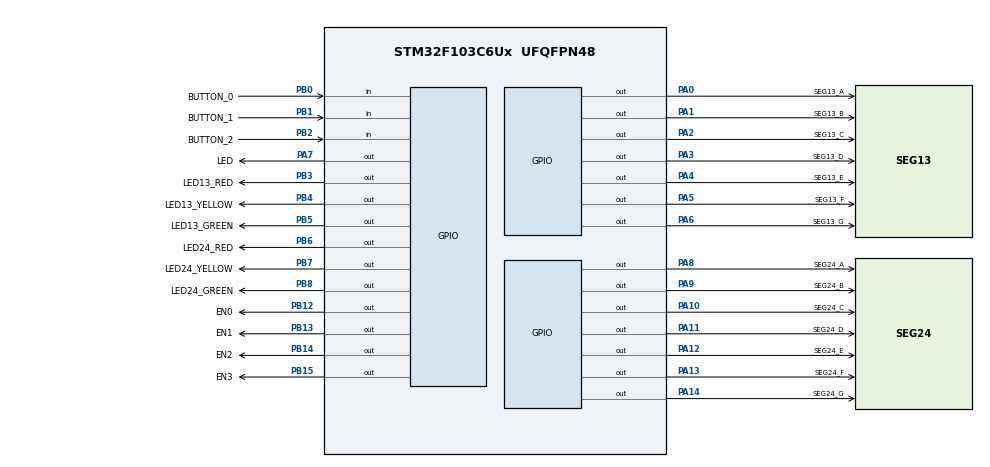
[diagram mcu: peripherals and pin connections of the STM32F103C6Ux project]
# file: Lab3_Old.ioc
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Mcu.Family=STM32F1
Mcu.Name=STM32F103C6Ux
Mcu.Package=UFQFPN48
NVIC.PriorityGroup=NVIC_PRIORITYGROUP_4
NVIC.TIM2_IRQn=true\:0\:0\:false\:false\:true\:true\:true\:true
PA0-WKUP.GPIO_Label=SEG13_A
PA0-WKUP.Signal=GPIO_Output
PA1.GPIO_Label=SEG13_B
PA1.Signal=GPIO_Output
PA10.GPIO_Label=SEG24_C
PA10.Signal=GPIO_Output
PA11.GPIO_Label=SEG24_D
PA11.Signal=GPIO_Output
PA12.GPIO_Label=SEG24_E
PA12.Signal=GPIO_Output
PA13.GPIO_Label=SEG24_F
PA13.Signal=GPIO_Output
PA14.GPIO_Label=SEG24_G
PA14.Signal=GPIO_Output
PA2.GPIO_Label=SEG13_C
PA2.Signal=GPIO_Output
PA3.GPIO_Label=SEG13_D
PA3.Signal=GPIO_Output
PA4.GPIO_Label=SEG13_E
PA4.Signal=GPIO_Output
PA5.GPIO_Label=SEG13_F
PA5.Signal=GPIO_Output
PA6.GPIO_Label=SEG13_G
PA6.Signal=GPIO_Output
PA7.GPIO_Label=LED
PA7.Signal=GPIO_Output
PA8.GPIO_Label=SEG24_A
PA8.Signal=GPIO_Output
PA9.GPIO_Label=SEG24_B
PA9.Signal=GPIO_Output
PB0.GPIO_Label=BUTTON_0
PB0.Signal=GPIO_Input
PB1.GPIO_Label=BUTTON_1
PB1.Signal=GPIO_Input
PB12.GPIO_Label=EN0
PB12.Signal=GPIO_Output
PB13.GPIO_Label=EN1
PB13.Signal=GPIO_Output
PB14.GPIO_Label=EN2
PB14.Signal=GPIO_Output
PB15.GPIO_Label=EN3
PB15.Signal=GPIO_Output
PB2.GPIO_Label=BUTTON_2
PB2.Signal=GPIO_Input
PB3.GPIO_Label=LED13_RED
PB3.Signal=GPIO_Output
PB4.GPIO_Label=LED13_YELLOW
PB4.Signal=GPIO_Output
PB5.GPIO_Label=LED13_GREEN
PB5.Signal=GPIO_Output
PB6.GPIO_Label=LED24_RED
PB6.Signal=GPIO_Output
PB7.GPIO_Label=LED24_YELLOW
PB7.Signal=GPIO_Output
PB8.GPIO_Label=LED24_GREEN
PB8.Signal=GPIO_Output
ProjectManager.HeapSize=0x200
ProjectManager.StackSize=0x400
ProjectManager.TargetToolchain=STM32CubeIDE
RCC.APB1Freq_Value=8000000
RCC.APB2Freq_Value=8000000
TIM2.Period=9
TIM2.Prescaler=7999
VP_SYS_VS_ND.Mode=No_Debug
VP_TIM2_VS_ClockSourceINT.Mode=Internal
board=custom

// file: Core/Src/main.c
/* USER CODE BEGIN Header */
/**
  ******************************************************************************
  * @file           : main.c
  * @brief          : Main program body
  ******************************************************************************
  * @attention
  *
  * Copyright (c) 2024 STMicroelectronics.
  * All rights reserved.
  *
  * This software is licensed under terms that can be found in the LICENSE file
  * in the root directory of this software component.
  * If no LICENSE file comes with this software, it is provided AS-IS.
  *
  ******************************************************************************
  */
/* USER CODE END Header */
#include "main.h"

/* USER CODE BEGIN Includes */
#include "input_processing.h"
#include "timer.h"
#include "fsm.h"
/* USER CODE END Includes */

TIM_HandleTypeDef htim2;

void SystemClock_Config(void);
static void MX_GPIO_Init(void);
static void MX_TIM2_Init(void);
/* USER CODE BEGIN PFP */
void HAL_TIM_PeriodElapsedCallback(TIM_HandleTypeDef *htim);
/* USER CODE END PFP */

/* USER CODE BEGIN 0 */
void HAL_TIM_PeriodElapsedCallback(TIM_HandleTypeDef *htim)
{
	if(htim->Instance == TIM2){
		button_reading();
		runTimer();
		/*Just for debug
		HAL_GPIO_TogglePin(CHECK_GPIO_Port, CHECK_Pin);*/
	}
}
/* USER CODE END 0 */

int main(void)
{

  /* MCU Configuration--------------------------------------------------------*/

  /* Reset of all peripherals, Initializes the Flash interface and the Systick. */
  HAL_Init();

  /* Configure the system clock */
  SystemClock_Config();

  /* Initialize all configured peripherals */
  MX_GPIO_Init();
  MX_TIM2_Init();

  /* Infinite loop */
  /* USER CODE BEGIN WHILE */
  setEnviromentStateInit();
  HAL_TIM_Base_Start_IT(&htim2);
  while (1)
  {
	/*Just for debug*/
	//display7SEG_13(FSM_State);
	//display7SEG_24(buttonState[0]);
//	if(is_button_pressed(0)){
//		HAL_GPIO_TogglePin(LED_GPIO_Port, LED_Pin);
//	}

	/* This branch just for implement scanning 7Seg led
	 * and debug when it run wrong
	 */

	fsm_for_input_processing();
	runFSM();
	run7Seg();
	runBlinkingLed();
    /* USER CODE END WHILE */

  }
}

void SystemClock_Config(void)
{
  RCC_OscInitTypeDef RCC_OscInitStruct = {0};
  RCC_ClkInitTypeDef RCC_ClkInitStruct = {0};

  /** Initializes the RCC Oscillators according to the specified parameters
  * in the RCC_OscInitTypeDef structure.
  */
  RCC_OscInitStruct.OscillatorType = RCC_OSCILLATORTYPE_HSI;
  RCC_OscInitStruct.HSIState = RCC_HSI_ON;
  RCC_OscInitStruct.HSICalibrationValue = RCC_HSICALIBRATION_DEFAULT;
  RCC_OscInitStruct.PLL.PLLState = RCC_PLL_NONE;
  if (HAL_RCC_OscConfig(&RCC_OscInitStruct) != HAL_OK)
  {
    Error_Handler();
  }

  /** Initializes the CPU, AHB and APB buses clocks
  */
  RCC_ClkInitStruct.ClockType = RCC_CLOCKTYPE_HCLK|RCC_CLOCKTYPE_SYSCLK
                              |RCC_CLOCKTYPE_PCLK1|RCC_CLOCKTYPE_PCLK2;
  RCC_ClkInitStruct.SYSCLKSource = RCC_SYSCLKSOURCE_HSI;
  RCC_ClkInitStruct.AHBCLKDivider = RCC_SYSCLK_DIV1;
  RCC_ClkInitStruct.APB1CLKDivider = RCC_HCLK_DIV1;
  RCC_ClkInitStruct.APB2CLKDivider = RCC_HCLK_DIV1;

  if (HAL_RCC_ClockConfig(&RCC_ClkInitStruct, FLASH_LATENCY_0) != HAL_OK)
  {
    Error_Handler();
  }
}

static void MX_TIM2_Init(void)
{

  TIM_ClockConfigTypeDef sClockSourceConfig = {0};
  TIM_MasterConfigTypeDef sMasterConfig = {0};

  htim2.Instance = TIM2;
  htim2.Init.Prescaler = 7999;
  htim2.Init.CounterMode = TIM_COUNTERMODE_UP;
  htim2.Init.Period = 9;
  htim2.Init.ClockDivision = TIM_CLOCKDIVISION_DIV1;
  htim2.Init.AutoReloadPreload = TIM_AUTORELOAD_PRELOAD_DISABLE;
  if (HAL_TIM_Base_Init(&htim2) != HAL_OK)
  {
    Error_Handler();
  }
  sClockSourceConfig.ClockSource = TIM_CLOCKSOURCE_INTERNAL;
  if (HAL_TIM_ConfigClockSource(&htim2, &sClockSourceConfig) != HAL_OK)
  {
    Error_Handler();
  }
  sMasterConfig.MasterOutputTrigger = TIM_TRGO_RESET;
  sMasterConfig.MasterSlaveMode = TIM_MASTERSLAVEMODE_DISABLE;
  if (HAL_TIMEx_MasterConfigSynchronization(&htim2, &sMasterConfig) != HAL_OK)
  {
    Error_Handler();
  }

}

static void MX_GPIO_Init(void)
{
  GPIO_InitTypeDef GPIO_InitStruct = {0};

  /* GPIO Ports Clock Enable */
  __HAL_RCC_GPIOA_CLK_ENABLE();
  __HAL_RCC_GPIOB_CLK_ENABLE();

  /*Configure GPIO pin Output Level */
  HAL_GPIO_WritePin(GPIOA, SEG13_A_Pin|SEG13_B_Pin|SEG13_C_Pin|SEG13_D_Pin
                          |SEG13_E_Pin|SEG13_F_Pin|SEG13_G_Pin|LED_Pin
                          |SEG24_A_Pin|SEG24_B_Pin|SEG24_C_Pin|SEG24_D_Pin
                          |SEG24_E_Pin|SEG24_F_Pin|SEG24_G_Pin, GPIO_PIN_RESET);

  /*Configure GPIO pin Output Level */
  HAL_GPIO_WritePin(GPIOB, EN0_Pin|EN1_Pin|EN2_Pin|EN3_Pin
                          |LED13_RED_Pin|LED13_YELLOW_Pin|LED13_GREEN_Pin|LED24_RED_Pin
                          |LED24_YELLOW_Pin|LED24_GREEN_Pin, GPIO_PIN_RESET);

  /*Configure GPIO pins : SEG13_A_Pin SEG13_B_Pin SEG13_C_Pin SEG13_D_Pin
                           SEG13_E_Pin SEG13_F_Pin SEG13_G_Pin LED_Pin
                           SEG24_A_Pin SEG24_B_Pin SEG24_C_Pin SEG24_D_Pin
                           SEG24_E_Pin SEG24_F_Pin SEG24_G_Pin */
  GPIO_InitStruct.Pin = SEG13_A_Pin|SEG13_B_Pin|SEG13_C_Pin|SEG13_D_Pin
                          |SEG13_E_Pin|SEG13_F_Pin|SEG13_G_Pin|LED_Pin
                          |SEG24_A_Pin|SEG24_B_Pin|SEG24_C_Pin|SEG24_D_Pin
                          |SEG24_E_Pin|SEG24_F_Pin|SEG24_G_Pin;
  GPIO_InitStruct.Mode = GPIO_MODE_OUTPUT_PP;
  GPIO_InitStruct.Pull = GPIO_NOPULL;
  GPIO_InitStruct.Speed = GPIO_SPEED_FREQ_LOW;
  HAL_GPIO_Init(GPIOA, &GPIO_InitStruct);

  /*Configure GPIO pins : BUTTON_0_Pin BUTTON_1_Pin BUTTON_2_Pin */
  GPIO_InitStruct.Pin = BUTTON_0_Pin|BUTTON_1_Pin|BUTTON_2_Pin;
  GPIO_InitStruct.Mode = GPIO_MODE_INPUT;
  GPIO_InitStruct.Pull = GPIO_NOPULL;
  HAL_GPIO_Init(GPIOB, &GPIO_InitStruct);

  /*Configure GPIO pins : EN0_Pin EN1_Pin EN2_Pin EN3_Pin
                           LED13_RED_Pin LED13_YELLOW_Pin LED13_GREEN_Pin LED24_RED_Pin
                           LED24_YELLOW_Pin LED24_GREEN_Pin */
  GPIO_InitStruct.Pin = EN0_Pin|EN1_Pin|EN2_Pin|EN3_Pin
                          |LED13_RED_Pin|LED13_YELLOW_Pin|LED13_GREEN_Pin|LED24_RED_Pin
                          |LED24_YELLOW_Pin|LED24_GREEN_Pin;
  GPIO_InitStruct.Mode = GPIO_MODE_OUTPUT_PP;
  GPIO_InitStruct.Pull = GPIO_NOPULL;
  GPIO_InitStruct.Speed = GPIO_SPEED_FREQ_LOW;
  HAL_GPIO_Init(GPIOB, &GPIO_InitStruct);

}

void Error_Handler(void)
{
  __disable_irq();
  while (1)
  {
  }
}
